VERSION ""

NS_ :

BS_:

BU_: PDM1 Tester ZGW

BO_ 144 PDM1_LoadStatus: 12 PDM1
 SG_ PDM1_LoadStatus_01 : 0|32@1+ (1,0) [0|4294967295] ""  ZGW
 SG_ PDM1_LoadStatus_02 : 32|32@1+ (1,0) [0|4294967295] ""  ZGW
 SG_ PDM1_LoadStatus_03 : 64|32@1+ (1,0) [0|4294967295] ""  ZGW

BO_ 262 InfotainmentData1: 12 ZGW
 SG_ IT1_MileageTrip : 56|32@1+ (1,0) [0|4294967295] ""  Tester
 SG_ IT1_MileageTotal : 24|32@1+ (1,0) [0|4294967295] ""  Tester
 SG_ IT1_DisplayCameraStatus : 16|8@1+ (1,0) [0|255] ""  Tester
 SG_ IT1_CommandDisplayErrorMessage : 8|8@1+ (1,0) [0|255] ""  Tester
 SG_ IT1_AliveIndication : 0|1@1+ (1,0) [0|1] ""  Tester

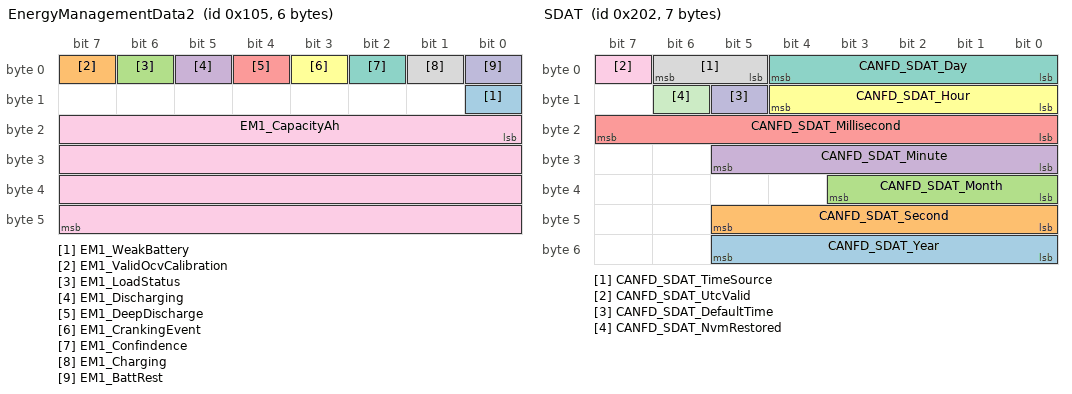
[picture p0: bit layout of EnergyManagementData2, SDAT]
BO_ 261 EnergyManagementData2: 6 ZGW
 SG_ EM1_WeakBattery : 8|1@1+ (1,0) [0|1] ""  Tester
 SG_ EM1_ValidOcvCalibration : 7|1@1+ (1,0) [0|1] ""  Tester
 SG_ EM1_LoadStatus : 6|1@1+ (1,0) [0|0] ""  Tester
 SG_ EM1_Discharging : 5|1@1+ (1,0) [0|1] ""  Tester
 SG_ EM1_DeepDischarge : 4|1@1+ (1,0) [0|1] ""  Tester
 SG_ EM1_CrankingEvent : 3|1@1+ (1,0) [0|1] ""  Tester
 SG_ EM1_Confindence : 2|1@1+ (1,0) [0|1] ""  Tester
 SG_ EM1_Charging : 1|1@1+ (1,0) [0|1] ""  Tester
 SG_ EM1_CapacityAh : 16|32@1- (1,0) [-3.4E+38|3.4E+38] ""  Tester
 SG_ EM1_BattRest : 0|1@1+ (1,0) [0|1] ""  Tester

BO_ 260 EnergyManagementData1: 64 ZGW
 SG_ EM1_TimeToFull : 480|32@1- (1,0) [-3.4E+38|3.4E+38] ""  Tester
 SG_ EM1_T30Voltage : 80|16@1+ (1,0) [0|65535] ""  Tester
 SG_ EM1_Soh : 448|32@1- (1,0) [-3.4E+38|3.4E+38] ""  Tester
 SG_ EM1_SocOcv : 416|32@1- (1,0) [-3.4E+38|3.4E+38] ""  Tester
 SG_ EM1_SocHybrid : 384|32@1- (1,0) [-3.4E+38|3.4E+38] ""  Tester
 SG_ EM1_SocCoulomb : 352|32@1- (1,0) [-3.4E+38|3.4E+38] ""  Tester
 SG_ EM1_RuntimeRemaining : 320|32@1- (1,0) [-3.4E+38|3.4E+38] ""  Tester
 SG_ EM1_McuTemp : 288|32@1- (1,0) [-3.4E+38|3.4E+38] ""  Tester
 SG_ EM1_L1Voltage : 64|16@1+ (1,0) [0|65535] ""  Tester
 SG_ EM1_L1Temp : 256|32@1- (1,0) [-3.4E+38|3.4E+38] ""  Tester
 SG_ EM1_L1ISense : 224|32@1- (1,0) [-3.4E+38|3.4E+38] ""  Tester
 SG_ EM1_IntResistance : 192|32@1- (1,0) [-3.4E+38|3.4E+38] ""  Tester
 SG_ EM1_I2TCounter : 160|32@1+ (1,0) [0|4294967295] ""  Tester
 SG_ EM1_DischargeAh : 128|32@1- (1,0) [-3.4E+38|3.4E+38] ""  Tester
 SG_ EM1_ChargeAh : 96|32@1- (1,0) [-3.4E+38|3.4E+38] ""  Tester
 SG_ EM1_AvgDischargeCurrent : 32|32@1- (1,0) [-3.4E+38|3.4E+38] ""  Tester
 SG_ EM1_AvgChargeCurrent : 0|32@1- (1,0) [-3.4E+38|3.4E+38] ""  Tester

BO_ 928 VehicleState: 1 ZGW
 SG_ VehicleStatus : 0|4@1+ (1,0) [0|15] ""  Tester

BO_ 1023 NM3: 1 ZGW
 SG_ Nm3_Pn1 : 0|8@1+ (1,0) [0|255] ""  Tester

BO_ 514 SDAT: 7 ZGW
 SG_ CANFD_SDAT_Year : 48|6@1+ (1,0) [0|63] ""  Tester
 SG_ CANFD_SDAT_Second : 40|6@1+ (1,0) [0|63] ""  Tester
 SG_ CANFD_SDAT_Month : 32|4@1+ (1,0) [0|15] ""  Tester
 SG_ CANFD_SDAT_Minute : 24|6@1+ (1,0) [0|63] ""  Tester
 SG_ CANFD_SDAT_Millisecond : 16|8@1+ (4,0) [0|1020] "ms"  Tester
 SG_ CANFD_SDAT_Hour : 8|5@1+ (1,0) [0|31] ""  Tester
 SG_ CANFD_SDAT_Day : 0|5@1+ (1,0) [0|31] ""  Tester
 SG_ CANFD_SDAT_TimeSource : 5|2@1+ (1,0) [0|3] ""  Tester
 SG_ CANFD_SDAT_UtcValid : 7|1@1+ (1,0) [0|1] ""  Tester
 SG_ CANFD_SDAT_DefaultTime : 13|1@1+ (1,0) [0|1] ""  Tester
 SG_ CANFD_SDAT_NvmRestored : 14|1@1+ (1,0) [0|1] ""  Tester

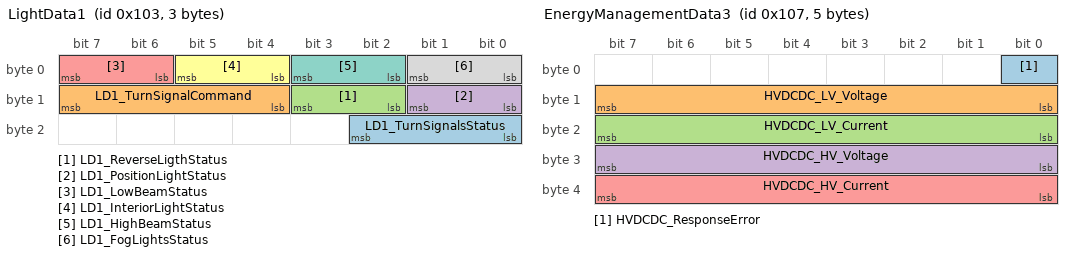
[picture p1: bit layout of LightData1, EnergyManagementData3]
BO_ 259 LightData1: 3 ZGW
 SG_ LD1_TurnSignalsStatus : 16|3@1+ (1,0) [0|7] ""  Tester
 SG_ LD1_TurnSignalCommand : 12|4@1+ (1,0) [0|15] ""  Tester
 SG_ LD1_ReverseLigthStatus : 10|2@1+ (1,0) [0|3] ""  Tester
 SG_ LD1_PositionLightStatus : 8|2@1+ (1,0) [0|3] ""  Tester
 SG_ LD1_LowBeamStatus : 6|2@1+ (1,0) [0|3] ""  Tester
 SG_ LD1_InteriorLightStatus : 4|2@1+ (1,0) [0|3] ""  Tester
 SG_ LD1_HighBeamStatus : 2|2@1+ (1,0) [0|3] ""  Tester
 SG_ LD1_FogLightsStatus : 0|2@1+ (1,0) [0|3] ""  Tester

BO_ 256 BodyData1: 20 ZGW
 SG_ BD1_WiperStockCommand : 128|8@1+ (1,0) [0|255] ""  Tester
 SG_ BD1_VibrationSensorStatus : 120|8@1+ (1,0) [0|255] ""  Tester
 SG_ BD1_StatusWipers : 109|3@1+ (1,0) [0|7] ""  Tester
 SG_ BD1_StatusDoors : 112|6@1+ (1,0) [0|63] ""  Tester
 SG_ BD1_RlsCommand : 104|5@1+ (1,0) [0|31] ""  Tester
 SG_ BD1_RecirculationCommand : 83|3@1+ (1,0) [0|7] ""  Tester
 SG_ BD1_PdcDistanceRear : 96|7@1+ (1,0) [0|127] ""  Tester
 SG_ BD1_PdcDistanceFront : 88|7@1+ (1,0) [0|127] ""  Tester
 SG_ BD1_PdcBuzzerFrontRear : 80|3@1+ (1,0) [0|7] ""  Tester
 SG_ BD1_OutsideTemperature : 48|32@1- (1,0) [-3.4E+38|3.4E+38] ""  Tester
 SG_ BD1_LigthSensor : 40|8@1+ (1,0) [0|255] ""  Tester
 SG_ BD1_Ignition : 34|4@1+ (1,0) [0|15] ""  Tester
 SG_ BD1_HighBeamCommand : 32|2@1+ (1,0) [0|3] ""  Tester
 SG_ BD1_HC05ConnectionStatus : 30|2@1+ (1,0) [0|3] ""  Tester
 SG_ BD1_Gearbox : 20|3@1+ (1,0) [0|7] ""  Tester
 SG_ BD1_FogLightsCommand : 13|3@1+ (1,0) [0|7] ""  Tester
 SG_ BD1_ClimateTemperatureCommand : 24|6@1+ (1,0) [0|63] ""  Tester
 SG_ BD1_ClimateFanCommand : 16|4@1+ (1,0) [0|15] ""  Tester
 SG_ BD1_ClimateAutoCommand : 11|2@1+ (1,0) [0|3] ""  Tester
 SG_ BD1_CentralLockStatus : 8|3@1+ (1,0) [0|7] ""  Tester
 SG_ BD1_CentralLockCommand : 5|3@1+ (1,0) [0|7] ""  Tester
 SG_ BD1_CentralLockBuzzer : 3|2@1+ (1,0) [0|3] ""  Tester
 SG_ BD1_BrakeLightStatus : 0|3@1+ (1,0) [0|7] ""  Tester

BO_ 773 PDM1_CurrentFeedback_1: 64 PDM1
 SG_ PDM1_CurrFb_001 : 0|32@1+ (1,0) [0|4294967295] ""  ZGW
 SG_ PDM1_CurrFb_002 : 32|32@1+ (1,0) [0|4294967295] ""  ZGW
 SG_ PDM1_CurrFb_003 : 64|32@1+ (1,0) [0|4294967295] ""  ZGW
 SG_ PDM1_CurrFb_004 : 96|32@1+ (1,0) [0|4294967295] ""  ZGW
 SG_ PDM1_CurrFb_005 : 128|32@1+ (1,0) [0|4294967295] ""  ZGW
 SG_ PDM1_CurrFb_006 : 160|32@1+ (1,0) [0|4294967295] ""  ZGW
 SG_ PDM1_CurrFb_007 : 192|32@1+ (1,0) [0|4294967295] ""  ZGW
 SG_ PDM1_CurrFb_008 : 224|32@1+ (1,0) [0|4294967295] ""  ZGW
 SG_ PDM1_CurrFb_009 : 256|32@1+ (1,0) [0|4294967295] ""  ZGW
 SG_ PDM1_CurrFb_010 : 288|32@1+ (1,0) [0|4294967295] ""  ZGW
 SG_ PDM1_CurrFb_011 : 320|32@1+ (1,0) [0|4294967295] ""  ZGW
 SG_ PDM1_CurrFb_012 : 352|32@1+ (1,0) [0|4294967295] ""  ZGW
 SG_ PDM1_CurrFb_013 : 384|32@1+ (1,0) [0|4294967295] ""  ZGW
 SG_ PDM1_CurrFb_014 : 416|32@1+ (1,0) [0|4294967295] ""  ZGW
 SG_ PDM1_CurrFb_015 : 448|32@1+ (1,0) [0|4294967295] ""  ZGW
 SG_ PDM1_CurrFb_016 : 480|32@1+ (1,0) [0|4294967295] ""  ZGW

BO_ 774 PDM1_CurrentFeedback_2: 64 PDM1
 SG_ PDM1_CurrFb_017 : 0|32@1+ (1,0) [0|4294967295] ""  ZGW
 SG_ PDM1_CurrFb_018 : 32|32@1+ (1,0) [0|4294967295] ""  ZGW
 SG_ PDM1_CurrFb_019 : 64|32@1+ (1,0) [0|4294967295] ""  ZGW
 SG_ PDM1_CurrFb_020 : 96|32@1+ (1,0) [0|4294967295] ""  ZGW
 SG_ PDM1_CurrFb_021 : 128|32@1+ (1,0) [0|4294967295] ""  ZGW
 SG_ PDM1_CurrFb_022 : 160|32@1+ (1,0) [0|4294967295] ""  ZGW
 SG_ PDM1_CurrFb_023 : 192|32@1+ (1,0) [0|4294967295] ""  ZGW
 SG_ PDM1_CurrFb_024 : 224|32@1+ (1,0) [0|4294967295] ""  ZGW
 SG_ PDM1_CurrFb_025 : 256|32@1+ (1,0) [0|4294967295] ""  ZGW
 SG_ PDM1_CurrFb_026 : 288|32@1+ (1,0) [0|4294967295] ""  ZGW
 SG_ PDM1_CurrFb_027 : 320|32@1+ (1,0) [0|4294967295] ""  ZGW
 SG_ PDM1_CurrFb_028 : 352|32@1+ (1,0) [0|4294967295] ""  ZGW
 SG_ PDM1_CurrFb_029 : 384|32@1+ (1,0) [0|4294967295] ""  ZGW
 SG_ PDM1_CurrFb_030 : 416|32@1+ (1,0) [0|4294967295] ""  ZGW
 SG_ PDM1_CurrFb_031 : 448|32@1+ (1,0) [0|4294967295] ""  ZGW
 SG_ PDM1_CurrFb_032 : 480|32@1+ (1,0) [0|4294967295] ""  ZGW

BO_ 775 PDM1_CurrentFeedback_3: 64 PDM1
 SG_ PDM1_CurrFb_033 : 0|32@1+ (1,0) [0|4294967295] ""  ZGW
 SG_ PDM1_CurrFb_034 : 32|32@1+ (1,0) [0|4294967295] ""  ZGW
 SG_ PDM1_CurrFb_035 : 64|32@1+ (1,0) [0|4294967295] ""  ZGW
 SG_ PDM1_CurrFb_036 : 96|32@1+ (1,0) [0|4294967295] ""  ZGW
 SG_ PDM1_CurrFb_037 : 128|32@1+ (1,0) [0|4294967295] ""  ZGW
 SG_ PDM1_CurrFb_038 : 160|32@1+ (1,0) [0|4294967295] ""  ZGW
 SG_ PDM1_CurrFb_039 : 192|32@1+ (1,0) [0|4294967295] ""  ZGW
 SG_ PDM1_CurrFb_040 : 224|32@1+ (1,0) [0|4294967295] ""  ZGW
 SG_ PDM1_CurrFb_041 : 256|32@1+ (1,0) [0|4294967295] ""  ZGW
 SG_ PDM1_CurrFb_042 : 288|32@1+ (1,0) [0|4294967295] ""  ZGW
 SG_ PDM1_CurrFb_043 : 320|32@1+ (1,0) [0|4294967295] ""  ZGW
 SG_ PDM1_CurrFb_044 : 352|32@1+ (1,0) [0|4294967295] ""  ZGW
 SG_ PDM1_CurrFb_045 : 384|32@1+ (1,0) [0|4294967295] ""  ZGW
 SG_ PDM1_CurrFb_046 : 416|32@1+ (1,0) [0|4294967295] ""  ZGW
 SG_ PDM1_CurrFb_047 : 448|32@1+ (1,0) [0|4294967295] ""  ZGW
 SG_ PDM1_CurrFb_048 : 480|32@1+ (1,0) [0|4294967295] ""  ZGW

BO_ 776 PDM1_CurrentFeedback_4: 64 PDM1
 SG_ PDM1_CurrFb_049 : 0|32@1+ (1,0) [0|4294967295] ""  ZGW
 SG_ PDM1_CurrFb_050 : 32|32@1+ (1,0) [0|4294967295] ""  ZGW
 SG_ PDM1_CurrFb_051 : 64|32@1+ (1,0) [0|4294967295] ""  ZGW
 SG_ PDM1_CurrFb_052 : 96|32@1+ (1,0) [0|4294967295] ""  ZGW
 SG_ PDM1_CurrFb_053 : 128|32@1+ (1,0) [0|4294967295] ""  ZGW
 SG_ PDM1_CurrFb_054 : 160|32@1+ (1,0) [0|4294967295] ""  ZGW
 SG_ PDM1_CurrFb_055 : 192|32@1+ (1,0) [0|4294967295] ""  ZGW
 SG_ PDM1_CurrFb_056 : 224|32@1+ (1,0) [0|4294967295] ""  ZGW
 SG_ PDM1_CurrFb_057 : 256|32@1+ (1,0) [0|4294967295] ""  ZGW
 SG_ PDM1_CurrFb_058 : 288|32@1+ (1,0) [0|4294967295] ""  ZGW
 SG_ PDM1_CurrFb_059 : 320|32@1+ (1,0) [0|4294967295] ""  ZGW
 SG_ PDM1_CurrFb_060 : 352|32@1+ (1,0) [0|4294967295] ""  ZGW
 SG_ PDM1_CurrFb_061 : 384|32@1+ (1,0) [0|4294967295] ""  ZGW
 SG_ PDM1_CurrFb_062 : 416|32@1+ (1,0) [0|4294967295] ""  ZGW
 SG_ PDM1_CurrFb_063 : 448|32@1+ (1,0) [0|4294967295] ""  ZGW
 SG_ PDM1_CurrFb_064 : 480|32@1+ (1,0) [0|4294967295] ""  ZGW

BO_ 777 PDM1_CurrentFeedback_5: 48 PDM1
 SG_ PDM1_CurrFb_065 : 0|32@1+ (1,0) [0|4294967295] ""  ZGW
 SG_ PDM1_CurrFb_066 : 32|32@1+ (1,0) [0|4294967295] ""  ZGW
 SG_ PDM1_CurrFb_067 : 64|32@1+ (1,0) [0|4294967295] ""  ZGW
 SG_ PDM1_CurrFb_068 : 96|32@1+ (1,0) [0|4294967295] ""  ZGW
 SG_ PDM1_CurrFb_069 : 128|32@1+ (1,0) [0|4294967295] ""  ZGW
 SG_ PDM1_CurrFb_070 : 160|32@1+ (1,0) [0|4294967295] ""  ZGW
 SG_ PDM1_CurrFb_071 : 192|32@1+ (1,0) [0|4294967295] ""  ZGW
 SG_ PDM1_CurrFb_072 : 224|32@1+ (1,0) [0|4294967295] ""  ZGW
 SG_ PDM1_CurrFb_073 : 256|32@1+ (1,0) [0|4294967295] ""  ZGW
 SG_ PDM1_CurrFb_074 : 288|32@1+ (1,0) [0|4294967295] ""  ZGW
 SG_ PDM1_CurrFb_075 : 320|32@1+ (1,0) [0|4294967295] ""  ZGW

BO_ 778 PDM1_InputT30: 2 PDM1
 SG_ InputT30 : 0|16@1+ (1,0) [0|65535] ""  ZGW

BO_ 128 CommandLoad_PDM1: 12 ZGW
 SG_ PDM1_CommandLoad_01 : 0|32@1+ (1,0) [0|4294967295] ""  PDM1
 SG_ PDM1_CommandLoad_02 : 32|32@1+ (1,0) [0|4294967295] ""  PDM1
 SG_ PDM1_CommandLoad_03 : 64|32@1+ (1,0) [0|4294967295] ""  PDM1

BO_ 263 EnergyManagementData3: 5 ZGW
 SG_ HVDCDC_ResponseError : 0|1@1+ (1,0) [0|1] ""  Tester
 SG_ HVDCDC_LV_Voltage : 8|8@1+ (1,0) [0|255] ""  Tester
 SG_ HVDCDC_LV_Current : 16|8@1+ (1,0) [0|255] ""  Tester
 SG_ HVDCDC_HV_Voltage : 24|8@1+ (1,0) [0|255] ""  Tester
 SG_ HVDCDC_HV_Current : 32|8@1+ (1,0) [0|255] ""  Tester

CM_ SG_ 514 CANFD_SDAT_Year "UTC year minus 2000, ZGW saturates values above 2063 to raw 63.";
CM_ SG_ 514 CANFD_SDAT_Millisecond "UTC millisecond encoded with 4 ms resolution.";
CM_ SG_ 514 CANFD_SDAT_TimeSource "0=default compile-time UTC, 1=UDS RoutineControl set time, 2=gPTP master, 3=invalid/unavailable.";
CM_ SG_ 514 CANFD_SDAT_UtcValid "1 when UTC/calendar fields are valid for display.";
CM_ SG_ 514 CANFD_SDAT_DefaultTime "1 when UTC comes from the compile-time default and shall be shown as not synchronized.";
CM_ SG_ 514 CANFD_SDAT_NvmRestored "1 when UTC was restored from NvM, no powered-off elapsed time is added without an external RTC.";

BA_DEF_ BO_ "GenMsgCycleTime" INT 0 10000;
BA_DEF_ BO_ "VFrameFormat" ENUM "StandardCAN","ExtendedCAN","reserved","reserved","reserved","reserved","reserved","reserved","reserved","reserved","reserved","reserved","reserved","reserved","StandardCAN_FD","ExtendedCAN_FD";
BA_DEF_ "BusType" STRING ;

BA_DEF_DEF_ "GenMsgCycleTime" 0;
BA_DEF_DEF_ "VFrameFormat" "StandardCAN";
BA_DEF_DEF_ "BusType" "";

BA_ "BusType" "CAN FD";
BA_ "GenMsgCycleTime" BO_ 514 800;
BA_ "GenMsgCycleTime" BO_ 144 1000;
BA_ "GenMsgCycleTime" BO_ 773 50;
BA_ "GenMsgCycleTime" BO_ 774 50;
BA_ "GenMsgCycleTime" BO_ 775 50;
BA_ "GenMsgCycleTime" BO_ 776 50;
BA_ "GenMsgCycleTime" BO_ 777 50;
BA_ "GenMsgCycleTime" BO_ 778 5;
BA_ "VFrameFormat" BO_ 144 14;
BA_ "VFrameFormat" BO_ 262 14;
BA_ "VFrameFormat" BO_ 261 14;
BA_ "VFrameFormat" BO_ 260 14;
BA_ "VFrameFormat" BO_ 928 14;
BA_ "VFrameFormat" BO_ 1023 14;
BA_ "VFrameFormat" BO_ 514 14;
BA_ "VFrameFormat" BO_ 259 14;
BA_ "VFrameFormat" BO_ 256 14;
BA_ "VFrameFormat" BO_ 773 14;
BA_ "VFrameFormat" BO_ 774 14;
BA_ "VFrameFormat" BO_ 775 14;
BA_ "VFrameFormat" BO_ 776 14;
BA_ "VFrameFormat" BO_ 777 14;
BA_ "VFrameFormat" BO_ 778 14;
BA_ "VFrameFormat" BO_ 128 14;
BA_ "VFrameFormat" BO_ 263 14;

VAL_ 514 CANFD_SDAT_TimeSource 0 "DefaultCompileTime" 1 "UdsRoutine" 2 "GptpMaster" 3 "Invalid" ;
VAL_ 514 CANFD_SDAT_UtcValid 0 "Invalid" 1 "Valid" ;
VAL_ 514 CANFD_SDAT_DefaultTime 0 "NotDefault" 1 "DefaultCompileTime" ;
VAL_ 514 CANFD_SDAT_NvmRestored 0 "NotRestored" 1 "RestoredFromNvM" ;

SIG_VALTYPE_ 261 EM1_CapacityAh : 1;
SIG_VALTYPE_ 260 EM1_TimeToFull : 1;
SIG_VALTYPE_ 260 EM1_Soh : 1;
SIG_VALTYPE_ 260 EM1_SocOcv : 1;
SIG_VALTYPE_ 260 EM1_SocHybrid : 1;
SIG_VALTYPE_ 260 EM1_SocCoulomb : 1;
SIG_VALTYPE_ 260 EM1_RuntimeRemaining : 1;
SIG_VALTYPE_ 260 EM1_McuTemp : 1;
SIG_VALTYPE_ 260 EM1_L1Temp : 1;
SIG_VALTYPE_ 260 EM1_L1ISense : 1;
SIG_VALTYPE_ 260 EM1_IntResistance : 1;
SIG_VALTYPE_ 260 EM1_DischargeAh : 1;
SIG_VALTYPE_ 260 EM1_ChargeAh : 1;
SIG_VALTYPE_ 260 EM1_AvgDischargeCurrent : 1;
SIG_VALTYPE_ 260 EM1_AvgChargeCurrent : 1;
